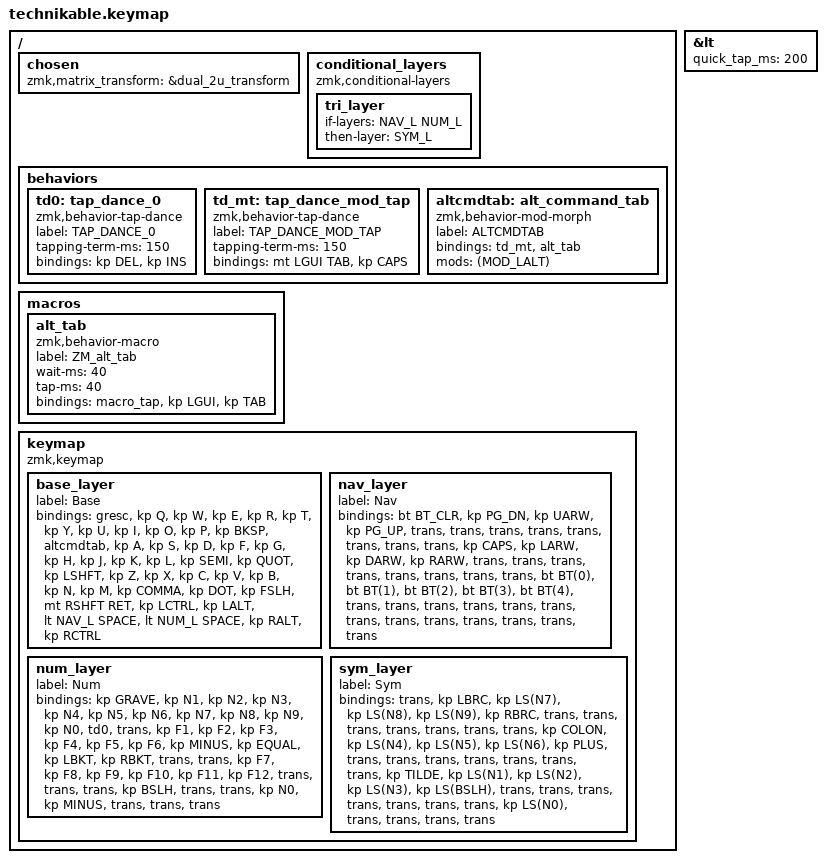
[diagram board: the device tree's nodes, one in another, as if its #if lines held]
/*
 * Copyright (c) 2022 Pete Johanson
 *
 * SPDX-License-Identifier: MIT
 */

#include <behaviors.dtsi>
#include <dt-bindings/zmk/keys.h>
#include <dt-bindings/zmk/bt.h>
#include <dt-bindings/zmk/outputs.h>

#define QWERTY_BASE 1

#define TBLE_ORTHO   true
// #define TBLE_MIT     true
// #define TBLE_DUAL_2U true

#define BAS_L 0
#define NAV_L 1
#define NUM_L 2
#define SYM_L 3

// Using layer taps on thumbs, having quick tap as well helps w/ repeating space/backspace
&lt { quick_tap_ms = <200>; };

#define BT(n) BT_SEL n

/ {
    chosen {
       zmk,matrix_transform =
#ifdef TBLE_DUAL_2U
                       &dual_2u_transform;
#elif defined(TBLE_MIT)
                       &mit_transform;
#else
                       &ortho_transform;
#endif
    };

    conditional_layers {
        compatible = "zmk,conditional-layers";
	tri_layer {
	    if-layers = <NAV_L NUM_L>;
	    then-layer = <SYM_L>;
	};
    };
    
    behaviors {
        td0: tap_dance_0 {
            compatible = "zmk,behavior-tap-dance";
            label = "TAP_DANCE_0";
            #binding-cells = <0>;
            tapping-term-ms = <150>;
            bindings = <&kp DEL>, <&kp INS>;
        };
	td_mt: tap_dance_mod_tap {
            compatible = "zmk,behavior-tap-dance";
            label = "TAP_DANCE_MOD_TAP";
            #binding-cells = <0>;
            tapping-term-ms = <150>;
            bindings = <&mt LGUI TAB>, <&kp CAPS>;
        };
	altcmdtab: alt_command_tab {
            compatible = "zmk,behavior-mod-morph";
            label = "ALTCMDTAB";
            #binding-cells = <0>;
            bindings = <&td_mt>, <&alt_tab>;
            mods = <(MOD_LALT)>;
        };
    };
    
    macros {
        alt_tab: alt_tab {
            label = "ZM_alt_tab";
            compatible = "zmk,behavior-macro";
            #binding-cells = <0>;
	    wait-ms = <40>;
	    tap-ms = <40>;
            bindings
                = <&macro_tap &kp LGUI &kp TAB>
                ;
        };
    };

    keymap {
        compatible = "zmk,keymap";

        base_layer {
            label = "Base";
            bindings = <
#ifdef QWERTY_BASE
 &gresc     &kp Q      &kp W      &kp E       &kp R          &kp T          &kp Y            &kp U          &kp I       &kp O      &kp P         &kp BKSP
 &altcmdtab   &kp A      &kp S      &kp D       &kp F          &kp G          &kp H            &kp J          &kp K       &kp L      &kp SEMI      &kp QUOT
 &kp LSHFT  &kp Z      &kp X      &kp C       &kp V          &kp B          &kp N            &kp M          &kp COMMA   &kp DOT    &kp FSLH      &mt RSHFT RET
#else
 &kp ESC    &kp Q      &kp W      &kp F       &kp P          &kp B          &kp J            &kp L          &kp U       &kp Y      &kp QUOT     &kp BKSP
 &kp TAB    &kp A      &kp R      &kp S       &kp T          &kp G          &kp M            &kp N          &kp E       &kp I      &kp O        &kp QUOT
 &kp LSHFT  &kp Z      &kp X      &kp C       &kp D          &kp V          &kp K            &kp H          &kp COMMA   &kp DOT    &kp FSLH     &kp RET
#endif
#ifdef TBLE_DUAL_2U
                       &kp LCTRL  &kp LALT      &lt NAV_L SPACE                &lt NUM_L SPACE              &kp RALT    &kp RCTRL
#elif defined(TBLE_MIT)
                       &kp LCTRL  &kp LALT    &mo NAV_L          &kp SPACE                   &mo NUM_L      &kp RALT    &kp RCTRL
#else
                       &kp LCTRL  &kp LALT    &lt NAV_L SPACE    &kp SPACE      &kp SPACE        &mo NUM_L      &kp RALT    &kp LGUI
#endif
            >;
        };

        nav_layer {
            label = "Nav";
            bindings = <
&bt BT_CLR &kp PG_DN  &kp UARW  &kp PG_UP   &trans          &trans       &trans     &trans       &trans     &trans     &trans     &trans
&kp CAPS   &kp LARW   &kp DARW  &kp RARW    &trans          &trans       &trans     &trans       &trans     &trans     &trans     &trans
&bt BT(0)  &bt BT(1)  &bt BT(2) &bt BT(3)   &bt BT(4)       &trans       &trans     &trans       &trans     &trans     &trans     &trans
#ifdef TBLE_DUAL_2U
                      &trans     &trans              &trans                    &trans       &trans         &trans
#elif defined(TBLE_MIT)
                      &trans     &trans      &trans                &trans             &trans      &trans   &trans
#else
                      &trans     &trans      &trans          &trans       &trans    &trans  &trans         &trans
#endif
            >;
        };

        num_layer {
            label = "Num";
            bindings = <
&kp GRAVE     &kp N1   &kp N2     &kp N3      &kp N4    &kp N5    &kp N6    &kp N7     &kp N8      &kp N9       &kp N0     &td0
&trans     &kp F1   &kp F2     &kp F3      &kp F4    &kp F5   &kp F6    &kp MINUS        &kp EQUAL       &kp LBKT       &kp RBKT     &trans
&trans     &kp F7  &kp F8     &kp F9      &kp F10    &kp F11   &kp F12        &trans         &trans       &trans       &kp BSLH     &trans
#ifdef TBLE_DUAL_2U
                     &trans     &kp N0              &kp MINUS                 &trans            &trans         &trans
#elif defined(TBLE_MIT)
                     &trans     &kp N0      &kp MINUS           &none            &kp ESC        &kp DEL      &trans
#else
                     &trans     &kp LGUI      &trans    &none         &none     &trans        &trans      &trans
#endif
            >;
        };

        sym_layer {
            label = "Sym";
            bindings = <
&trans     &kp LBRC   &kp LS(N7) &kp LS(N8)  &kp LS(N9)   &kp RBRC     &trans     &trans    &trans       &trans       &trans     &trans
&trans     &kp COLON  &kp LS(N4) &kp LS(N5)  &kp LS(N6)   &kp PLUS     &trans     &trans    &trans       &trans       &trans     &trans
&trans     &kp TILDE  &kp LS(N1) &kp LS(N2)  &kp LS(N3)   &kp LS(BSLH) &trans     &trans    &trans       &trans       &trans     &trans
#ifdef TBLE_DUAL_2U
                      &trans     &kp LS(N0)              &trans                    &trans       &trans         &trans
#elif defined(TBLE_MIT)
                      &trans     &kp LS(N0)      &trans                &trans             &trans      &trans   &trans
#else
                      &trans     &kp LS(N0)      &trans          &trans       &trans    &trans  &trans         &trans
#endif
            >;
        };

    };
};

